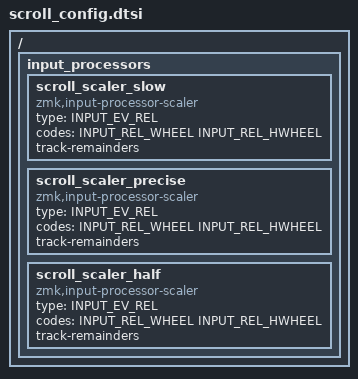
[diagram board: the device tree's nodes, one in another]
/*
 * スクロール感度設定ファイル
 * 
 * 感度調整方法:
 * - scroll_scaler_slow: 基本スクロール感度調整
 * - scroll_scaler_precise: より細かいスクロール用
 * 
 * 使用例:
 * &scroll_scaler_slow 1 3    -> 感度1/3 (推奨デフォルト)
 * &scroll_scaler_slow 1 5    -> 感度1/5 (より細かく)
 * &scroll_scaler_slow 2 3    -> 感度2/3 (少し下げる)
 * &scroll_scaler_slow 1 2    -> 感度1/2 (半分)
 */

/ {
    input_processors {
        // 基本スクロールスケーラー（推奨: 感度を1/3に）
        scroll_scaler_slow: scroll_scaler_slow {
            compatible = "zmk,input-processor-scaler";
            #input-processor-cells = <2>;
            type = <INPUT_EV_REL>;
            codes = <INPUT_REL_WHEEL INPUT_REL_HWHEEL>;
            track-remainders;
        };
        
        // 高精度スクロール用（感度を1/5に）
        scroll_scaler_precise: scroll_scaler_precise {
            compatible = "zmk,input-processor-scaler";
            #input-processor-cells = <2>;
            type = <INPUT_EV_REL>;
            codes = <INPUT_REL_WHEEL INPUT_REL_HWHEEL>;
            track-remainders;
        };

        // 微調整用（感度を1/2に）
        scroll_scaler_half: scroll_scaler_half {
            compatible = "zmk,input-processor-scaler";
            #input-processor-cells = <2>;
            type = <INPUT_EV_REL>;
            codes = <INPUT_REL_WHEEL INPUT_REL_HWHEEL>;
            track-remainders;
        };
    };
};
